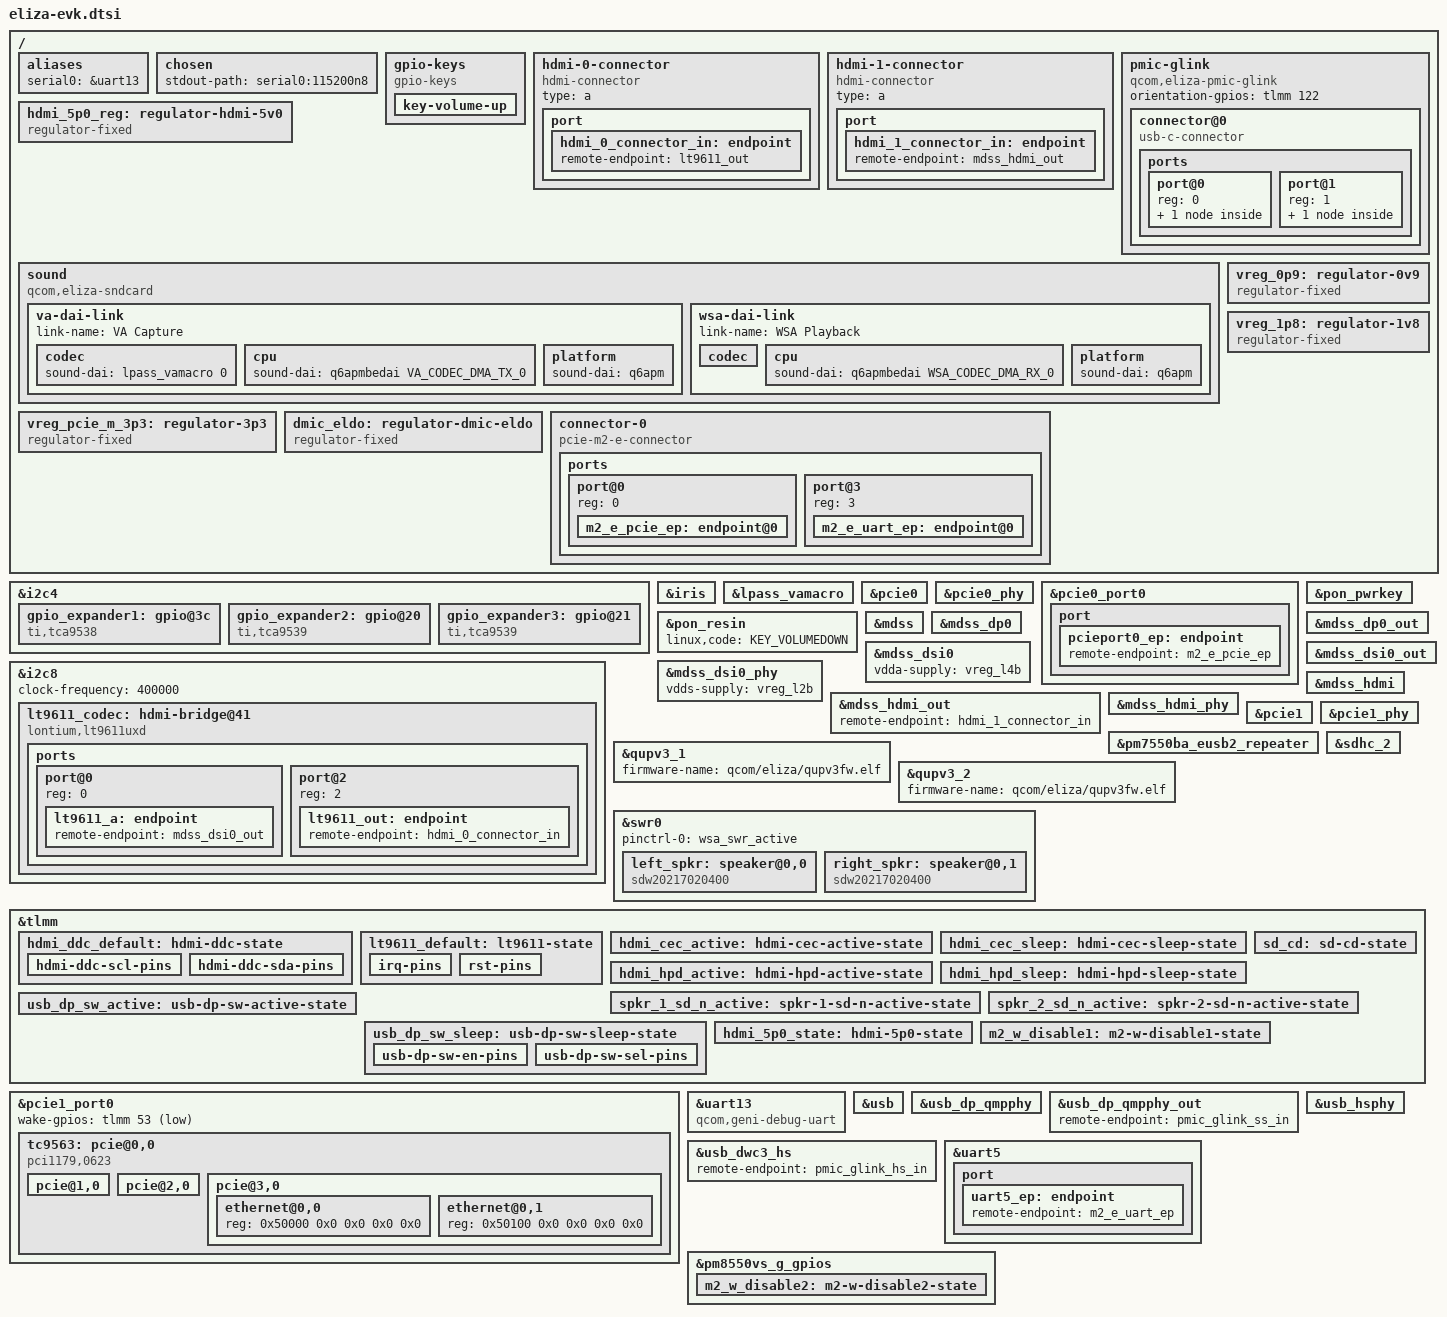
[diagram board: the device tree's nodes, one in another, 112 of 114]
// SPDX-License-Identifier: BSD-3-Clause
/*
 * Copyright (c) Qualcomm Technologies, Inc. and/or its subsidiaries.
 */

#include <dt-bindings/sound/qcom,q6dsp-lpass-ports.h>

/ {
	aliases {
		serial0 = &uart13;
	};

	chosen {
		stdout-path = "serial0:115200n8";
	};

	gpio-keys {
		compatible = "gpio-keys";

		key-volume-up {
			label = "Volume Up";
			linux,code = <KEY_VOLUMEUP>;
			gpios = <&pm7550_gpios 6 GPIO_ACTIVE_LOW>;
			debounce-interval = <10>;
			linux,can-disable;
			wakeup-source;
		};
	};

	hdmi-0-connector {
		compatible = "hdmi-connector";
		type = "a";

		port {
			hdmi_0_connector_in: endpoint {
				remote-endpoint = <&lt9611_out>;
			};
		};
	};

	hdmi-1-connector {
		compatible = "hdmi-connector";
		type = "a";

		port {
			hdmi_1_connector_in: endpoint {
				remote-endpoint = <&mdss_hdmi_out>;
			};
		};
	};

	pmic-glink {
		compatible = "qcom,eliza-pmic-glink",
			     "qcom,sm8550-pmic-glink",
			     "qcom,pmic-glink";
		#address-cells = <1>;
		#size-cells = <0>;
		orientation-gpios = <&tlmm 122 GPIO_ACTIVE_HIGH>;

		connector@0 {
			compatible = "usb-c-connector";
			reg = <0>;

			power-role = "dual";
			data-role = "dual";

			ports {
				#address-cells = <1>;
				#size-cells = <0>;

				port@0 {
					reg = <0>;

					pmic_glink_hs_in: endpoint {
						remote-endpoint = <&usb_dwc3_hs>;
					};
				};

				port@1 {
					reg = <1>;

					pmic_glink_ss_in: endpoint {
						remote-endpoint = <&usb_dp_qmpphy_out>;
					};
				};
/*
				port@2 {
					reg = <2>;

					pmic_glink_sbu: endpoint {
						remote-endpoint = <&wcd_usbss_sbu_mux>;
					};
				};
				*/
			};
		};
	};

	hdmi_5p0_reg: regulator-hdmi-5v0 {
		compatible = "regulator-fixed";
		regulator-name = "hdmi_5p0";

		regulator-min-microvolt = <5000000>;
		regulator-max-microvolt = <5000000>;
		gpio = <&tlmm 184 GPIO_ACTIVE_HIGH>;
		enable-active-high;
		pinctrl-0 = <&hdmi_5p0_state>;
		pinctrl-names = "default";
	};

	sound {
		compatible = "qcom,eliza-sndcard", "qcom,sm8450-sndcard";
		model = "eliza-cqs-evk";

		audio-routing = "SpkrLeft IN", "WSA_SPK1 OUT",
				"SpkrRight IN", "WSA_SPK2 OUT",
				"VA DMIC0", "vdd-micb",
				"VA DMIC1", "vdd-micb",
				"VA DMIC2", "vdd-micb",
				"VA DMIC3", "vdd-micb",
				"VA DMIC4", "vdd-micb",
				"VA DMIC5", "vdd-micb",
				"VA DMIC6", "vdd-micb",
				"VA DMIC7", "vdd-micb";

		va-dai-link {
			link-name = "VA Capture";

			codec {
				sound-dai = <&lpass_vamacro 0>;
			};

			cpu {
				sound-dai = <&q6apmbedai VA_CODEC_DMA_TX_0>;
			};

			platform {
				sound-dai = <&q6apm>;
			};
		};

		wsa-dai-link {
			link-name = "WSA Playback";

			codec {
				sound-dai = <&left_spkr>, <&right_spkr>,
					    <&swr0 0>, <&lpass_wsamacro 0>;
			};

			cpu {
				sound-dai = <&q6apmbedai WSA_CODEC_DMA_RX_0>;
			};

			platform {
				sound-dai = <&q6apm>;
			};
		};
	};

	vreg_0p9: regulator-0v9 {
		compatible = "regulator-fixed";
		regulator-name = "VREG_0P9";

		regulator-min-microvolt = <900000>;
		regulator-max-microvolt = <900000>;
		regulator-always-on;
		regulator-boot-on;
	};

	vreg_1p8: regulator-1v8 {
		compatible = "regulator-fixed";
		regulator-name = "VREG_1P8";

		regulator-min-microvolt = <1800000>;
		regulator-max-microvolt = <1800000>;
		regulator-always-on;
		regulator-boot-on;
	};

	vreg_pcie_m_3p3: regulator-3p3 {
		compatible = "regulator-fixed";

		regulator-name = "vreg_3p3";
		regulator-min-microvolt = <3300000>;
		regulator-max-microvolt = <3300000>;

		gpio = <&gpio_expander1 6 GPIO_ACTIVE_HIGH>;
		enable-active-high;
	};

	dmic_eldo: regulator-dmic-eldo {
		compatible = "regulator-fixed";
		regulator-name = "dmic-eldo";
		regulator-min-microvolt = <1800000>;
		regulator-max-microvolt = <1800000>;
		gpio = <&pm7550_gpios 8 GPIO_ACTIVE_HIGH>;
		enable-active-high;
		vin-supply = <&vreg_bob>;
	};

	connector-0 {
		compatible = "pcie-m2-e-connector";
		vpcie3v3-supply = <&vreg_pcie_m_3p3>;
		w-disable1-gpios = <&tlmm 35 GPIO_ACTIVE_LOW>;
		w-disable2-gpios = <&pm8550vs_g_gpios 4 GPIO_ACTIVE_HIGH>;

		pinctrl-0 = <&m2_w_disable1>, <&m2_w_disable2>;
		pinctrl-names = "default";

		ports {
			#address-cells = <1>;
			#size-cells = <0>;

			port@0 {
				reg = <0>;
				#address-cells = <1>;
				#size-cells = <0>;

				m2_e_pcie_ep: endpoint@0 {
					reg = <0>;
					remote-endpoint = <&pcieport0_ep>;
				};
			};

			port@3 {
				reg = <3>;
				#address-cells = <1>;
				#size-cells = <0>;

				m2_e_uart_ep: endpoint@0 {
					reg = <0>;
					remote-endpoint = <&uart5_ep>;
				};
			};
		};
	};
};

/*
&i2c3 {
	status = "okay";

	wcd_usbss: typec-mux@e {
		compatible = "qcom,wcd9395-usbss", "qcom,wcd9390-usbss";
		reg = <0xe>;

		vdd-supply = <&vreg_l7b>;
		reset-gpios = <&tlmm 151 GPIO_ACTIVE_HIGH>;

		mode-switch;
		orientation-switch;

		ports {
			#address-cells = <1>;
			#size-cells = <0>;

			port@0 {
				reg = <0>;

				wcd_usbss_sbu_mux: endpoint {
					remote-endpoint = <&pmic_glink_sbu>;
				};
			};

			port@1 {
				reg = <1>;

				wcd_usbss_headset_out: endpoint {
				};
			};
		};
	};
};
*/

&i2c4 {
	pinctrl-0 = <&qup_i2c4_data_clk>;
	pinctrl-names = "default";

	clock-frequency = <400000>;

	status = "okay";

	gpio_expander1: gpio@3c {
		compatible = "ti,tca9538";
		#gpio-cells = <2>;
		gpio-controller;
		reg = <0x3c>;
	};
};

&iris {
	status = "okay";
};

&lpass_vamacro {
	pinctrl-0 = <&dmic01_default>, <&dmic23_default>,
		    <&dmic45_default>, <&dmic67_default>;
	pinctrl-names = "default";

	vdd-micb-supply = <&dmic_eldo>;
	qcom,dmic-sample-rate = <4800000>;
};

&pcie0 {
	status = "okay";
};

&pcie0_phy {
	vdda-phy-supply = <&vreg_l1k>;
	vdda-pll-supply = <&vreg_l3k>;

	status = "okay";
};

&pcie0_port0 {
	wake-gpios = <&tlmm 114 GPIO_ACTIVE_LOW>;
	reset-gpios = <&tlmm 78 GPIO_ACTIVE_LOW>;

	port {
		pcieport0_ep: endpoint {
			remote-endpoint = <&m2_e_pcie_ep>;
		};
	};
};

&pon_pwrkey {
	status = "okay";
};

&pon_resin {
	linux,code = <KEY_VOLUMEDOWN>;
	status = "okay";
};

&i2c4 {
	clock-frequency = <400000>;

	status = "okay";

	gpio_expander2: gpio@20 {
		compatible = "ti,tca9539";
		reg = <0x20>;

		gpio-controller;
		#gpio-cells = <2>;
	};

	gpio_expander3: gpio@21 {
		compatible = "ti,tca9539";
		reg = <0x21>;

		gpio-controller;
		#gpio-cells = <2>;

		/* That's GPIO 184 instead, here only as input */
		/*
		hdmi-5p0-pwr-en-hog {
			gpio-hog;
			gpios = <4 GPIO_ACTIVE_HIGH>;
			output-high;
			line-name = "hdmi_5p0_pwr_en";
		};
		*/
	};
};

&i2c8 {
	clock-frequency = <400000>;

	status = "okay";

	lt9611_codec: hdmi-bridge@41 {
		compatible = "lontium,lt9611uxd";
		reg = <0x41>;

		interrupts-extended = <&tlmm 13 IRQ_TYPE_EDGE_FALLING>;
		reset-gpios = <&tlmm 16 GPIO_ACTIVE_HIGH>;

		vdd-supply = <&vph_pwr>;
		vcc-supply = <&vreg_l7b>;

		pinctrl-0 = <&lt9611_default>;
		pinctrl-names = "default";

		ports {
			#address-cells = <1>;
			#size-cells = <0>;

			port@0 {
				reg = <0>;

				lt9611_a: endpoint {
					remote-endpoint = <&mdss_dsi0_out>;
				};
			};

			port@2 {
				reg = <2>;

				lt9611_out: endpoint {
					remote-endpoint = <&hdmi_0_connector_in>;
				};
			};
		};
	};
};

&mdss {
	status = "okay";
};

&mdss_dp0 {
	/* TODO: l17b needed for USB DP switch */
	pinctrl-0 = <&usb_dp_sw_active>;
	pinctrl-1 = <&usb_dp_sw_sleep>;
	pinctrl-names = "default", "sleep";

	//status = "okay";
};

&mdss_dp0_out {
	link-frequencies = /bits/ 64 <1620000000 2700000000 5400000000 8100000000>;
};

&mdss_dsi0 {
	vdda-supply = <&vreg_l4b>;

	// status = "okay";
};

&mdss_dsi0_out {
	remote-endpoint = <&lt9611_a>;
	data-lanes = <0 1 2 3>;
};

&mdss_dsi0_phy {
	vdds-supply = <&vreg_l2b>;

	// status = "okay";
};

&mdss_hdmi {
	//hpd-gpios = <&tlmm 47 GPIO_ACTIVE_HIGH>;
#if 0
	pinctrl-0 = <&hdmi_ddc_default>,
		    <&hdmi_cec_active>,
		    <&hdmi_hpd_active>,
		    <&hdmi_earc_pwr_en_state>;
	pinctrl-1 = <&hdmi_ddc_default>,
		    <&hdmi_cec_sleep>,
		    <&hdmi_hpd_sleep>,
		    <&hdmi_earc_pwr_en_sleep>;
#endif
	pinctrl-0 = <&hdmi_ddc_default>,
		    <&hdmi_cec_active>,
		    <&hdmi_hpd_active>;
	pinctrl-1 = <&hdmi_ddc_default>,
		    <&hdmi_cec_sleep>,
		    <&hdmi_hpd_sleep>;
	pinctrl-names = "default", "sleep";

	core-vdda-supply = <&vreg_l4b>;
	core-vcc-supply = <&vreg_l2b>;
	vddio-supply = <&hdmi_5p0_reg>;

	status = "okay";
};

&mdss_hdmi_out {
	remote-endpoint = <&hdmi_1_connector_in>;
};

&mdss_hdmi_phy {
	status = "okay";
};

&pcie0 {
	wake-gpios = <&tlmm 114 GPIO_ACTIVE_HIGH>;
	perst-gpios = <&tlmm 78 GPIO_ACTIVE_LOW>;

	status = "okay";
};

&pcie0_phy {
	vdda-phy-supply = <&vreg_l1k>;
	vdda-pll-supply = <&vreg_l3k>;

	status = "okay";
};

&pcie1 {
	wake-gpios = <&tlmm 53 GPIO_ACTIVE_HIGH>;
	perst-gpios = <&tlmm 54 GPIO_ACTIVE_LOW>;

	status = "okay";
};

&pcie1_phy {
	vdda-phy-supply = <&vreg_l1k>;
	vdda-pll-supply = <&vreg_l3k>;
	vdda-qref-supply = <&vreg_l1k>;

	status = "okay";
};

&pm7550ba_eusb2_repeater {
	vdd18-supply = <&vreg_l7b>;
	vdd3-supply = <&vreg_l17b>;
};

&qupv3_1 {
	firmware-name = "qcom/eliza/qupv3fw.elf";
};

&qupv3_2 {
	firmware-name = "qcom/eliza/qupv3fw.elf";
};

&sdhc_2 {
	vmmc-supply = <&vreg_l13b>;
	vqmmc-supply = <&vreg_l23b>;

	cd-gpios = <&tlmm 58 GPIO_ACTIVE_LOW>;

	pinctrl-0 = <&sdc2_default>, <&sd_cd>;
	pinctrl-1 = <&sdc2_sleep>, <&sd_cd>;
	pinctrl-names = "default", "sleep";

	status = "okay";
};

&swr0 {
	pinctrl-0 = <&wsa_swr_active>;
	pinctrl-names = "default";

	status = "okay";

	/* WSA8845, Speaker Left */
	left_spkr: speaker@0,0 {
		compatible = "sdw20217020400";
		reg = <0 0>;
		pinctrl-0 = <&spkr_1_sd_n_active>;
		pinctrl-names = "default";
		powerdown-gpios = <&tlmm 59 GPIO_ACTIVE_LOW>;
		vdd-1p8-supply = <&vreg_l7b>;
		vdd-io-supply = <&vreg_l7b>;

		#sound-dai-cells = <0>;
		sound-name-prefix = "SpkrLeft";

		/*
		 * WSA8845 Port 1 (DAC)     <=> SWR0 Port 1  (SPKR_L)
		 * WSA8845 Port 2 (COMP)    <=> SWR0 Port 2  (SPKR_L_COMP)
		 * WSA8845 Port 3 (BOOST)   <=> SWR0 Port 3  (SPKR_L_BOOST)
		 * WSA8845 Port 4 (PBR)     <=> SWR0 Port 7  (PBR)
		 * WSA8845 Port 5 (VISENSE) <=> SWR0 Port 10 (SPKR_L_VI)
		 * WSA8845 Port 6 (CPS)     <=> SWR0 Port 13 (CPS)
		 */
		qcom,port-mapping = <1 2 3 7 10 13>;
	};

	/* WSA8845, Speaker Right */
	right_spkr: speaker@0,1 {
		compatible = "sdw20217020400";
		reg = <0 1>;
		pinctrl-0 = <&spkr_2_sd_n_active>;
		pinctrl-names = "default";
		powerdown-gpios = <&tlmm 79 GPIO_ACTIVE_LOW>;
		vdd-1p8-supply = <&vreg_l7b>;
		vdd-io-supply = <&vreg_l7b>;

		#sound-dai-cells = <0>;
		sound-name-prefix = "SpkrRight";

		/*
		 * WSA8845 Port 1 (DAC)     <=> SWR0 Port 4  (SPKR_R)
		 * WSA8845 Port 2 (COMP)    <=> SWR0 Port 5  (SPKR_R_COMP)
		 * WSA8845 Port 3 (BOOST)   <=> SWR0 Port 6  (SPKR_R_BOOST)
		 * WSA8845 Port 4 (PBR)     <=> SWR0 Port 7  (PBR)
		 * WSA8845 Port 5 (VISENSE) <=> SWR0 Port 11 (SPKR_R_VI)
		 * WSA8845 Port 6 (CPS)     <=> SWR0 Port 13 (CPS)
		 */
		qcom,port-mapping = <4 5 6 7 11 13>;
	};
};

&tlmm {
	hdmi_ddc_default: hdmi-ddc-state {
		hdmi-ddc-scl-pins {
			pins = "gpio6";
			function = "hdmi_ddc_scl";
			drive-strength = <2>;
			bias-pull-up;
		};

		hdmi-ddc-sda-pins {
			pins = "gpio7";
			function = "hdmi_ddc_sda";
			drive-strength = <2>;
			bias-pull-up;
		};
	};

	lt9611_default: lt9611-state {
		irq-pins {
			pins = "gpio13";
			function = "gpio";
			bias-disable;
		};

		rst-pins {
			pins = "gpio16";
			function = "gpio";

			output-high;
		};
	};

	hdmi_cec_active: hdmi-cec-active-state {
		pins = "gpio46";
		function = "hdmi_tx_cec";
		drive-strength = <16>;
		bias-pull-up;
	};

	hdmi_cec_sleep: hdmi-cec-sleep-state {
		pins = "gpio46";
		function = "hdmi_tx_cec";
		drive-strength = <2>;
		bias-pull-up;
	};

	hdmi_hpd_active: hdmi-hpd-active-state {
		pins = "gpio47";
		function = "hdmi_hot_plug";
		drive-strength = <16>;
		bias-pull-down;
	};

	hdmi_hpd_sleep: hdmi-hpd-sleep-state {
		pins = "gpio47";
		function = "hdmi_hot_plug";
		drive-strength = <2>;
		bias-pull-down;
	};

	sd_cd: sd-cd-state {
		pins = "gpio58";
		function = "gpio";
		bias-pull-up;
	};

	spkr_1_sd_n_active: spkr-1-sd-n-active-state {
		pins = "gpio59";
		function = "gpio";
		drive-strength = <16>;
		bias-disable;
	};

	spkr_2_sd_n_active: spkr-2-sd-n-active-state {
		pins = "gpio79";
		function = "gpio";
		drive-strength = <16>;
		bias-disable;
	};

	usb_dp_sw_active: usb-dp-sw-active-state {
		pins = "gpio177", "gpio178";
		function = "gpio";
		drive-strength = <8>;
		bias-disable;
		output-high;
	};

	usb_dp_sw_sleep: usb-dp-sw-sleep-state {
		usb-dp-sw-en-pins {
			pins = "gpio177";
			function = "gpio";
			drive-strength = <8>;
			bias-disable;
			output-high;
		};

		usb-dp-sw-sel-pins {
			pins = "gpio178";
			function = "gpio";
			drive-strength = <8>;
			bias-disable;
			output-low;
		};
	};

	/*
	 * Based on schematics, but not downstream. Necessary to enable SIL9437
	 * IC for eARC, which when non-working seems to pull down HPD
	 * permanently when 5p0 is on and reverse (pull up when 5p0 is off) -
	 * no clue what is happening here.
	 */
	 /*
	hdmi_earc_pwr_en_active: hdmi-earc-pwr-en-active-state {
		pins = "gpio180";
		function = "gpio";
		drive-strength = <8>;
		bias-disable;
		//output-high;
		output-low;
	};

	hdmi_earc_pwr_en_sleep: hdmi-earc-pwr-en-sleep-state {
		pins = "gpio180";
		function = "gpio";
		drive-strength = <8>;
		bias-disable;
		//output-high;
		output-low;
	};
	*/


	hdmi_5p0_state: hdmi-5p0-state {
		pins = "gpio184";
		function = "gpio";
		drive-strength = <8>;
		bias-disable;
		output-low;
	};
};

&pcie1 {
	iommu-map = <0x0 &apps_smmu 0x1400 0x0 0x1>,
		    <0x100 &apps_smmu 0x1401 0x0 0x1>,
		    <0x208 &apps_smmu 0x1402 0x0 0x1>,
		    <0x210 &apps_smmu 0x1403 0x0 0x1>,
		    <0x218 &apps_smmu 0x1404 0x0 0x1>,
		    <0x300 &apps_smmu 0x1405 0x0 0x1>,
		    <0x400 &apps_smmu 0x1406 0x0 0x1>,
		    <0x500 &apps_smmu 0x1407 0x0 0x1>,
		    <0x501 &apps_smmu 0x1408 0x0 0x1>;

	status = "okay";
};

&pcie1_phy {
	vdda-phy-supply = <&vreg_l1k>;
	vdda-pll-supply = <&vreg_l3k>;

	status = "okay";
};

&pcie1_port0 {
	wake-gpios = <&tlmm 53 GPIO_ACTIVE_LOW>;
	/* Same GPIO is used for both PERST# and resx-gpio */

	tc9563: pcie@0,0 {
		compatible = "pci1179,0623";
		reg = <0x10000 0x0 0x0 0x0 0x0>;
		#address-cells = <3>;
		#size-cells = <2>;

		device_type = "pci";
		ranges;
		bus-range = <0x2 0xff>;

		vddc-supply = <&vreg_0p9>;
		vdd18-supply = <&vreg_1p8>;
		vdd09-supply = <&vreg_0p9>;
		vddio1-supply = <&vreg_1p8>;
		vddio2-supply = <&vreg_1p8>;
		vddio18-supply = <&vreg_1p8>;

		i2c-parent = <&i2c4 0x77>;

		resx-gpios = <&tlmm 54 GPIO_ACTIVE_LOW>;

		pcie@1,0 {
			reg = <0x20800 0x0 0x0 0x0 0x0>;
			#address-cells = <3>;
			#size-cells = <2>;

			device_type = "pci";
			ranges;
			bus-range = <0x3 0xff>;
		};

		pcie@2,0 {
			reg = <0x21000 0x0 0x0 0x0 0x0>;
			#address-cells = <3>;
			#size-cells = <2>;

			device_type = "pci";
			ranges;
			bus-range = <0x4 0xff>;
		};

		pcie@3,0 {
			reg = <0x21800 0x0 0x0 0x0 0x0>;
			#address-cells = <3>;
			#size-cells = <2>;
			device_type = "pci";
			ranges;
			bus-range = <0x5 0xff>;

			ethernet@0,0 {
				reg = <0x50000 0x0 0x0 0x0 0x0>;
			};

			ethernet@0,1 {
				reg = <0x50100 0x0 0x0 0x0 0x0>;
			};
		};
	};
};

&uart13 {
	compatible = "qcom,geni-debug-uart";

	status = "okay";
};

&usb {
	status = "okay";
};

&usb_dp_qmpphy {
	vdda-phy-supply = <&vreg_l3g>;
	vdda-pll-supply = <&vreg_l7k>;

	status = "okay";
};

&usb_dp_qmpphy_out {
	remote-endpoint = <&pmic_glink_ss_in>;
};

&usb_dwc3_hs {
	remote-endpoint = <&pmic_glink_hs_in>;
};

&usb_hsphy {
	vdd-supply = <&vreg_l7k>;
	vdda12-supply = <&vreg_l4b>;

	phys = <&pm7550ba_eusb2_repeater>;

	status = "okay";
};

&uart5 {
	status = "okay";

	port {
		uart5_ep: endpoint {
			remote-endpoint = <&m2_e_uart_ep>;
		};
	};
};

&pm8550vs_g_gpios {
	m2_w_disable2: m2-w-disable2-state {
		pins = "gpio4";
		function = "normal";
		input-disable;
		output-enable;
		bias-disable;
		power-source = <2>;
	};
};

&tlmm {
	m2_w_disable1: m2-w-disable1-state {
		pins = "gpio35";
		function = "gpio";
		drive-strength = <2>;
		bias-pull-up;
	};
};
